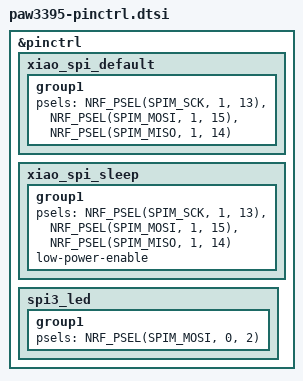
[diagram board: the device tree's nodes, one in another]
// Pin control configuration for PAW3395 shield

&pinctrl {
    // SPI2 (xiao_spi) for PAW3395 sensor - D8/D9/D10
    xiao_spi_default: xiao_spi_default {
        group1 {
            psels = <NRF_PSEL(SPIM_SCK, 1, 13)>,   // D8 (P1.13)
                    <NRF_PSEL(SPIM_MOSI, 1, 15)>,  // D10 (P1.15)
                    <NRF_PSEL(SPIM_MISO, 1, 14)>;  // D9 (P1.14)
        };
    };

    xiao_spi_sleep: xiao_spi_sleep {
        group1 {
            psels = <NRF_PSEL(SPIM_SCK, 1, 13)>,
                    <NRF_PSEL(SPIM_MOSI, 1, 15)>,
                    <NRF_PSEL(SPIM_MISO, 1, 14)>;
            low-power-enable;
        };
    };

    // SPI3 for LED strip on D0
    spi3_led: spi3_led {
        group1 {
            psels = <NRF_PSEL(SPIM_MOSI, 0, 2)>;  // D0 (P0.2) for WS2812 LEDs
        };
    };
};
